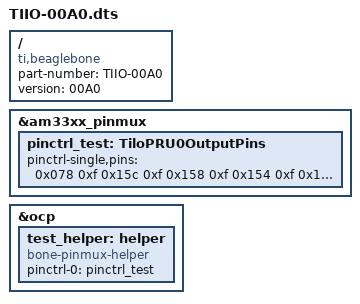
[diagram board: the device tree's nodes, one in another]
/dts-v1/;
/plugin/;

/{
        compatible = "ti,beaglebone", "ti,beaglebone-black";
        part-number = "TIIO-00A0";
        version = "00A0";
        fragment@0 {
            target = <&am33xx_pinmux>;
            __overlay__ {
                pinctrl_test: TiloPRU0OutputPins {
                    pinctrl-single,pins = <
                        /* 0x184 ((1 << 5) |(1 << 4) | 2)  P9_24: uart1_txd.d_can1_rx */
                        /* 0x180 ((1 << 4) | 2)             P9_26: uart1_rxd.d_can1_tx */
                        /* 0x074 (0 | 6)                    P9_13: gpmc_wpn.uart4_txd_mux2 */
                        /* 0x070 ((1 << 8)  | 6)            P9_11: gpmc_wait0.uart4_rxd_mux2 */
                        0x078 0xf                       /* BONE_P9_12 0x078 PIN_OUTPUT*/    
                        0x15c 0xf                       /* BONE_P9_17 0x15c PIN_OUTPUT*/    
                        0x158 0xf                       /* BONE_P9_18 0x158 PIN_OUTPUT*/    
                        0x154 0xf                       /* BONE_P9_21 0x154 PIN_OUTPUT*/   
                        0x150 0xf                       /* BONE_P9_22 0x150 PIN_OUTPUT*/  
                        0x098 0xf			/* BONE_P8_10 0x098 PIN_OUTPUT*/
                        0x07C 0x2F                      /* BONE_P8_26 0x07C PIN_INPUT  */
                    >;
                };
            };
        };

        fragment@1 {
            target = <&ocp>;
            __overlay__ {
                test_helper: helper {
                    compatible = "bone-pinmux-helper";
                    pinctrl-names = "default";
                    pinctrl-0 = <&pinctrl_test>;
                    status = "okay";
                };
            };
        };
};
